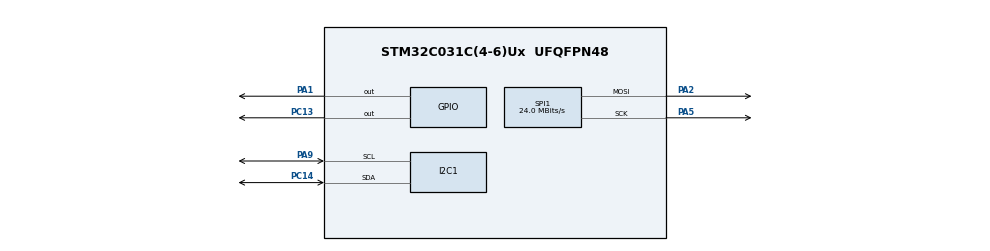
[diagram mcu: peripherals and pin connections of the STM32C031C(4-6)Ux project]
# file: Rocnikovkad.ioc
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I2C1.Timing=0x10805D88
Mcu.Family=STM32C0
Mcu.Name=STM32C031C(4-6)Ux
Mcu.Package=UFQFPN48
PA1.Signal=GPIO_Output
PA13.Mode=Serial_Wire
PA13.Signal=DEBUG_SWDIO
PA14-BOOT0.Mode=Serial_Wire
PA14-BOOT0.Signal=DEBUG_SWCLK
PA2.Mode=TX_Only_Simplex_Unidirect_Master
PA2.Signal=SPI1_MOSI
PA4.Signal=ADC1_IN4
PA5.Mode=TX_Only_Simplex_Unidirect_Master
PA5.Signal=SPI1_SCK
PA9.Mode=I2C
PA9.Signal=I2C1_SCL
PB4.Signal=SPI1_MISO
PC13.Signal=GPIO_Output
PC14-OSCX_IN\ (PC14).Mode=I2C
PC14-OSCX_IN\ (PC14).Signal=I2C1_SDA
PF0-OSC_IN\ (PF0).Mode=HSE-External-Oscillator
PF0-OSC_IN\ (PF0).Signal=RCC_OSC_IN
PF1-OSC_OUT\ (PF1).Mode=HSE-External-Oscillator
PF1-OSC_OUT\ (PF1).Signal=RCC_OSC_OUT
ProjectManager.HeapSize=0x200
ProjectManager.StackSize=0x400
ProjectManager.TargetToolchain=STM32CubeIDE
RCC.ADCFreq_Value=48000000
RCC.AHBFreq_Value=48000000
RCC.CortexFreq_Value=48000000
RCC.EXTERNAL_CLOCK_VALUE=12288000
RCC.HCLKFreq_Value=48000000
RCC.HSE_VALUE=48000000
RCC.HSI_VALUE=48000000
RCC.LSE_VALUE=32768
RCC.SYSCLKFreq_VALUE=48000000
RCC.SYSCLKSource=RCC_SYSCLKSOURCE_HSE
SPI1.CalculateBaudRate=24.0 MBits/s
SPI1.Direction=SPI_DIRECTION_2LINES
SPI1.Mode=SPI_MODE_MASTER
SPI1.VirtualType=VM_MASTER
board=custom

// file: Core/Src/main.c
/* USER CODE BEGIN Header */
/**
  ******************************************************************************
  * @file           : main.c
  * @brief          : Main program body
  ******************************************************************************
  * @attention
  *
  * Copyright (c) 2025 STMicroelectronics.
  * All rights reserved.
  *
  * This software is licensed under terms that can be found in the LICENSE file
  * in the root directory of this software component.
  * If no LICENSE file comes with this software, it is provided AS-IS.
  *
  ******************************************************************************
  */
/* USER CODE END Header */
#include "main.h"
#include "i2c.h"
#include "spi.h"
#include "gpio.h"

void SystemClock_Config(void);

int main(void)
{

  /* MCU Configuration--------------------------------------------------------*/

  /* Reset of all peripherals, Initializes the Flash interface and the Systick. */
  HAL_Init();

  /* Configure the system clock */
  SystemClock_Config();

  /* Initialize all configured peripherals */
  MX_GPIO_Init();
  MX_I2C1_Init();
  MX_SPI1_Init();
  /* USER CODE BEGIN 2 */
	uint8_t dataSPI[4] = {0x01, 0x02, 0x03, 0x04};
	uint8_t dataI2C[3] = {0x10, 0x20, 0x30};
	unit8_t dataSPI2[2] = {0xF5, 0x11};
  /* USER CODE END 2 */

  /* Infinite loop */
  while (1)
  {
	  HAL_SPI_Transmit(SPI1, dataSPI, 4, 100); // 4 = lenSPI
	  HAL_I2C_Master_Transmit(&hi2c1, 0x50, dataI2C, 3, 100); // 3 = lenI2C
	  HAL_SPI_Transmit(SPI1, dataSPI2, 2, 100);

	  OLED_DrawNumber(0, 0, temperature);
  }
}

void SystemClock_Config(void)
{
  RCC_OscInitTypeDef RCC_OscInitStruct = {0};
  RCC_ClkInitTypeDef RCC_ClkInitStruct = {0};

  __HAL_FLASH_SET_LATENCY(FLASH_LATENCY_1);

  /** Initializes the RCC Oscillators according to the specified parameters
  * in the RCC_OscInitTypeDef structure.
  */
  RCC_OscInitStruct.OscillatorType = RCC_OSCILLATORTYPE_HSE;
  RCC_OscInitStruct.HSEState = RCC_HSE_ON;
  if (HAL_RCC_OscConfig(&RCC_OscInitStruct) != HAL_OK)
  {
    Error_Handler();
  }

  /** Initializes the CPU, AHB and APB buses clocks
  */
  RCC_ClkInitStruct.ClockType = RCC_CLOCKTYPE_HCLK|RCC_CLOCKTYPE_SYSCLK
                              |RCC_CLOCKTYPE_PCLK1;
  RCC_ClkInitStruct.SYSCLKSource = RCC_SYSCLKSOURCE_HSE;
  RCC_ClkInitStruct.SYSCLKDivider = RCC_SYSCLK_DIV1;
  RCC_ClkInitStruct.AHBCLKDivider = RCC_HCLK_DIV1;
  RCC_ClkInitStruct.APB1CLKDivider = RCC_APB1_DIV1;

  if (HAL_RCC_ClockConfig(&RCC_ClkInitStruct, FLASH_LATENCY_1) != HAL_OK)
  {
    Error_Handler();
  }
}

void Error_Handler(void)
{
  __disable_irq();
  while (1)
  {
  }
}
